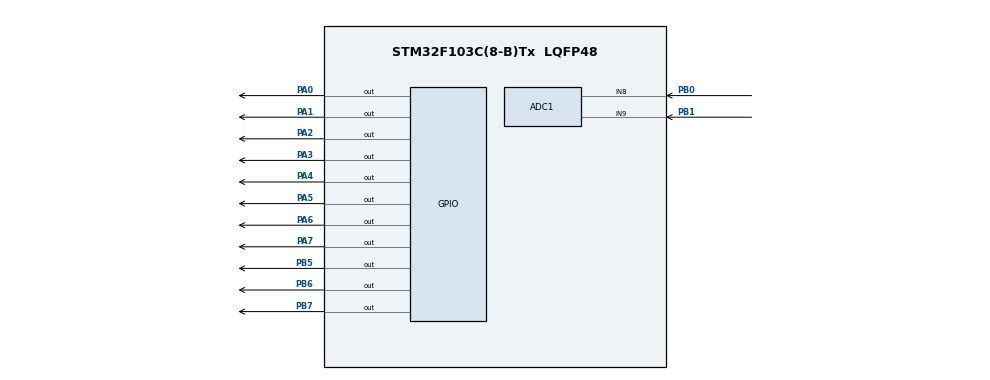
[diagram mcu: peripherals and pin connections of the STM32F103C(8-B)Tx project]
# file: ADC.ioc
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ADC1.Channel-1\#ChannelRegularConversion=ADC_CHANNEL_8
ADC1.Channel-2\#ChannelRegularConversion=ADC_CHANNEL_9
ADC1.NbrOfConversion=2
ADC1.NbrOfConversionFlag=1
ADC1.Rank-1\#ChannelRegularConversion=1
ADC1.Rank-2\#ChannelRegularConversion=2
ADC1.SamplingTime-1\#ChannelRegularConversion=ADC_SAMPLETIME_71CYCLES_5
ADC1.SamplingTime-2\#ChannelRegularConversion=ADC_SAMPLETIME_239CYCLES_5
ADC1.master=1
Mcu.Family=STM32F1
Mcu.Name=STM32F103C(8-B)Tx
Mcu.Package=LQFP48
NVIC.PriorityGroup=NVIC_PRIORITYGROUP_4
PA0-WKUP.Signal=GPIO_Output
PA1.Signal=GPIO_Output
PA13.Mode=Serial_Wire
PA13.Signal=SYS_JTMS-SWDIO
PA14.Mode=Serial_Wire
PA14.Signal=SYS_JTCK-SWCLK
PA2.Signal=GPIO_Output
PA3.Signal=GPIO_Output
PA4.Signal=GPIO_Output
PA5.Signal=GPIO_Output
PA6.Signal=GPIO_Output
PA7.Signal=GPIO_Output
PB0.Signal=ADCx_IN8
PB1.Signal=ADCx_IN9
PB5.Signal=GPIO_Output
PB6.Signal=GPIO_Output
PB7.Signal=GPIO_Output
PD0-OSC_IN.Mode=HSE-External-Oscillator
PD0-OSC_IN.Signal=RCC_OSC_IN
PD1-OSC_OUT.Mode=HSE-External-Oscillator
PD1-OSC_OUT.Signal=RCC_OSC_OUT
ProjectManager.HeapSize=0x200
ProjectManager.StackSize=0x400
ProjectManager.TargetToolchain=EWARM V8.32
RCC.APB1Freq_Value=8000000
RCC.APB2Freq_Value=8000000
RCC.SYSCLKSource=RCC_SYSCLKSOURCE_HSE
SH.ADCx_IN8.0=ADC1_IN8,IN8
SH.ADCx_IN9.0=ADC1_IN9,IN9
board=custom

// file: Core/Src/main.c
/* USER CODE BEGIN Header */
/**
  ******************************************************************************
  * @file           : main.c
  * @brief          : Main program body
  ******************************************************************************
  * @attention
  *
  * Copyright (c) 2024 STMicroelectronics.
  * All rights reserved.
  *
  * This software is licensed under terms that can be found in the LICENSE file
  * in the root directory of this software component.
  * If no LICENSE file comes with this software, it is provided AS-IS.
  *
  ******************************************************************************
  */
/* USER CODE END Header */
#include "main.h"

/* USER CODE BEGIN Includes */

#include "LCD/lcd.h"
#include <stdio.h>

/* USER CODE END Includes */

ADC_HandleTypeDef hadc1;

/* USER CODE BEGIN PV */

  char str1[17];
char str2[17];
float v1;
float v2;

/* USER CODE END PV */

void SystemClock_Config(void);
static void MX_GPIO_Init(void);
static void MX_ADC1_Init(void);

int main(void)
{

  /* MCU Configuration--------------------------------------------------------*/

  /* Reset of all peripherals, Initializes the Flash interface and the Systick. */
  HAL_Init();

  /* Configure the system clock */
  SystemClock_Config();

  /* Initialize all configured peripherals */
  MX_GPIO_Init();
  MX_ADC1_Init();

  /* Infinite loop */
  /* USER CODE BEGIN WHILE */

  lcd_init();
  lcd_clear();
  lcd_gotoxy(0,0);
  lcd_puts("Hi ADC...");
  HAL_Delay(2000);
  lcd_clear();

  while (1)
  {
    /* USER CODE END WHILE */

    hadc1.Init.NbrOfConversion=1;
    HAL_ADC_Init(&hadc1);
    HAL_ADC_Start(&hadc1);
    if(HAL_ADC_PollForConversion(&hadc1,10)==HAL_OK){

      v1 = HAL_ADC_GetValue(&hadc1);
      v1=(v1/4095)*3.3;
      sprintf(str1,"ADC1 =%0.2f ",v1);
      lcd_gotoxy(0,0);
      lcd_puts(str1);

    } ;

    HAL_ADC_Stop(&hadc1);

   // HAL_Delay(500);

    hadc1.Init.NbrOfConversion=2;
    HAL_ADC_Init(&hadc1);
    HAL_ADC_Start(&hadc1);
    if(HAL_ADC_PollForConversion(&hadc1,10)==HAL_OK){

      v2 = HAL_ADC_GetValue(&hadc1);
      v2=(v2/4095)*3.3;
      sprintf(str2,"ADC2 =%0.2f ",v2);
      lcd_gotoxy(0,1);
      lcd_puts(str2);

    } ;
    HAL_ADC_Stop(&hadc1);

  }
}

void SystemClock_Config(void)
{
  RCC_OscInitTypeDef RCC_OscInitStruct = {0};
  RCC_ClkInitTypeDef RCC_ClkInitStruct = {0};
  RCC_PeriphCLKInitTypeDef PeriphClkInit = {0};

  /** Initializes the RCC Oscillators according to the specified parameters
  * in the RCC_OscInitTypeDef structure.
  */
  RCC_OscInitStruct.OscillatorType = RCC_OSCILLATORTYPE_HSE;
  RCC_OscInitStruct.HSEState = RCC_HSE_ON;
  RCC_OscInitStruct.PLL.PLLState = RCC_PLL_NONE;
  if (HAL_RCC_OscConfig(&RCC_OscInitStruct) != HAL_OK)
  {
    Error_Handler();
  }

  /** Initializes the CPU, AHB and APB buses clocks
  */
  RCC_ClkInitStruct.ClockType = RCC_CLOCKTYPE_HCLK|RCC_CLOCKTYPE_SYSCLK
                              |RCC_CLOCKTYPE_PCLK1|RCC_CLOCKTYPE_PCLK2;
  RCC_ClkInitStruct.SYSCLKSource = RCC_SYSCLKSOURCE_HSE;
  RCC_ClkInitStruct.AHBCLKDivider = RCC_SYSCLK_DIV1;
  RCC_ClkInitStruct.APB1CLKDivider = RCC_HCLK_DIV1;
  RCC_ClkInitStruct.APB2CLKDivider = RCC_HCLK_DIV1;

  if (HAL_RCC_ClockConfig(&RCC_ClkInitStruct, FLASH_LATENCY_0) != HAL_OK)
  {
    Error_Handler();
  }
  PeriphClkInit.PeriphClockSelection = RCC_PERIPHCLK_ADC;
  PeriphClkInit.AdcClockSelection = RCC_ADCPCLK2_DIV2;
  if (HAL_RCCEx_PeriphCLKConfig(&PeriphClkInit) != HAL_OK)
  {
    Error_Handler();
  }
}

static void MX_ADC1_Init(void)
{

  ADC_ChannelConfTypeDef sConfig = {0};

  /** Common config
  */
  hadc1.Instance = ADC1;
  hadc1.Init.ScanConvMode = ADC_SCAN_ENABLE;
  hadc1.Init.ContinuousConvMode = DISABLE;
  hadc1.Init.DiscontinuousConvMode = DISABLE;
  hadc1.Init.ExternalTrigConv = ADC_SOFTWARE_START;
  hadc1.Init.DataAlign = ADC_DATAALIGN_RIGHT;
  hadc1.Init.NbrOfConversion = 2;
  if (HAL_ADC_Init(&hadc1) != HAL_OK)
  {
    Error_Handler();
  }

  /** Configure Regular Channel
  */
  sConfig.Channel = ADC_CHANNEL_8;
  sConfig.Rank = ADC_REGULAR_RANK_1;
  sConfig.SamplingTime = ADC_SAMPLETIME_71CYCLES_5;
  if (HAL_ADC_ConfigChannel(&hadc1, &sConfig) != HAL_OK)
  {
    Error_Handler();
  }

  /** Configure Regular Channel
  */
  sConfig.Channel = ADC_CHANNEL_9;
  sConfig.Rank = ADC_REGULAR_RANK_2;
  sConfig.SamplingTime = ADC_SAMPLETIME_239CYCLES_5;
  if (HAL_ADC_ConfigChannel(&hadc1, &sConfig) != HAL_OK)
  {
    Error_Handler();
  }

}

static void MX_GPIO_Init(void)
{
  GPIO_InitTypeDef GPIO_InitStruct = {0};

  /* GPIO Ports Clock Enable */
  __HAL_RCC_GPIOD_CLK_ENABLE();
  __HAL_RCC_GPIOA_CLK_ENABLE();
  __HAL_RCC_GPIOB_CLK_ENABLE();

  /*Configure GPIO pin Output Level */
  HAL_GPIO_WritePin(GPIOA, GPIO_PIN_0|GPIO_PIN_1|GPIO_PIN_2|GPIO_PIN_3
                          |GPIO_PIN_4|GPIO_PIN_5|GPIO_PIN_6|GPIO_PIN_7, GPIO_PIN_RESET);

  /*Configure GPIO pin Output Level */
  HAL_GPIO_WritePin(GPIOB, GPIO_PIN_5|GPIO_PIN_6|GPIO_PIN_7, GPIO_PIN_RESET);

  /*Configure GPIO pins : PA0 PA1 PA2 PA3
                           PA4 PA5 PA6 PA7 */
  GPIO_InitStruct.Pin = GPIO_PIN_0|GPIO_PIN_1|GPIO_PIN_2|GPIO_PIN_3
                          |GPIO_PIN_4|GPIO_PIN_5|GPIO_PIN_6|GPIO_PIN_7;
  GPIO_InitStruct.Mode = GPIO_MODE_OUTPUT_PP;
  GPIO_InitStruct.Pull = GPIO_NOPULL;
  GPIO_InitStruct.Speed = GPIO_SPEED_FREQ_LOW;
  HAL_GPIO_Init(GPIOA, &GPIO_InitStruct);

  /*Configure GPIO pins : PB5 PB6 PB7 */
  GPIO_InitStruct.Pin = GPIO_PIN_5|GPIO_PIN_6|GPIO_PIN_7;
  GPIO_InitStruct.Mode = GPIO_MODE_OUTPUT_PP;
  GPIO_InitStruct.Pull = GPIO_NOPULL;
  GPIO_InitStruct.Speed = GPIO_SPEED_FREQ_LOW;
  HAL_GPIO_Init(GPIOB, &GPIO_InitStruct);

}

void Error_Handler(void)
{
  __disable_irq();
  while (1)
  {
  }
}
